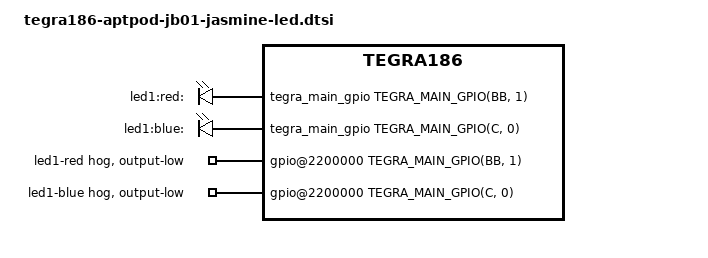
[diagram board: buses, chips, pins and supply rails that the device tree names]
/ {
	leds {
		compatible = "gpio-leds";
        status = "okay";

        led1_red {
            label = "led1:red:";
            gpios = <&tegra_main_gpio TEGRA_MAIN_GPIO(BB, 1) GPIO_ACTIVE_HIGH>;	/* GPIO14_AP_WAKE_MDM */
            default-state = "off";
            linux,default-trigger = "none";
        };
        led1_blue {
            label = "led1:blue:";
            gpios = <&tegra_main_gpio TEGRA_MAIN_GPIO(C, 0) GPIO_ACTIVE_HIGH>;	/* GPIO10_WIFI_WAKE_AP */
            default-state = "on";
            linux,default-trigger = "disk-activity";
        };
	};

	gpio@2200000 {
		led1-control-red {
			gpio-hog;
			gpios = <TEGRA_MAIN_GPIO(BB, 1) GPIO_ACTIVE_HIGH>;
			output-low;
			label = "led1-red";
			status = "okay";
		};

		led1-control-blue {
			gpio-hog;
			gpios = <TEGRA_MAIN_GPIO(C, 0) GPIO_ACTIVE_HIGH>;
			output-low;
			label = "led1-blue";
			status = "okay";
		};
	};
};
